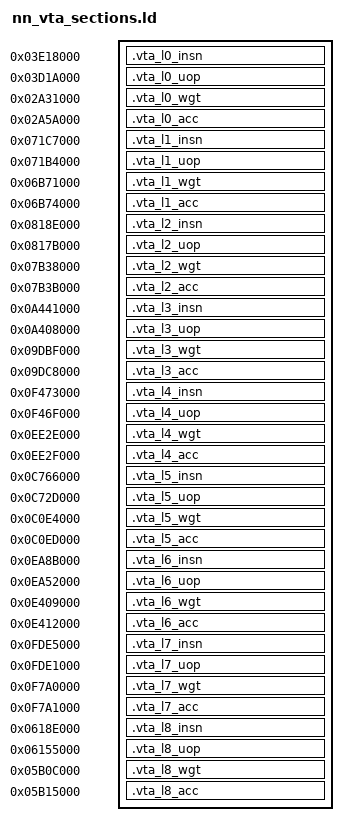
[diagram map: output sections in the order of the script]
/* Auto-generated by gen_nn_baremetal.py - DO NOT EDIT              */
/* VTA static model data linker fragment                             */
/*                                                                   */
/* Include this file inside the platform linker script generated.                    */
/* Example (in your lscript.ld):           */
/*   INCLUDE ../gen/nn_vta_sections.ld                                */

SECTIONS {
.vta_l0_insn 0x03E18000 : { KEEP(*(.vta_l0_insn)) }
.vta_l0_uop 0x03D1A000 : { KEEP(*(.vta_l0_uop)) }
.vta_l0_wgt 0x02A31000 : { KEEP(*(.vta_l0_wgt)) }
.vta_l0_acc 0x02A5A000 : { KEEP(*(.vta_l0_acc)) }
.vta_l1_insn 0x071C7000 : { KEEP(*(.vta_l1_insn)) }
.vta_l1_uop 0x071B4000 : { KEEP(*(.vta_l1_uop)) }
.vta_l1_wgt 0x06B71000 : { KEEP(*(.vta_l1_wgt)) }
.vta_l1_acc 0x06B74000 : { KEEP(*(.vta_l1_acc)) }
.vta_l2_insn 0x0818E000 : { KEEP(*(.vta_l2_insn)) }
.vta_l2_uop 0x0817B000 : { KEEP(*(.vta_l2_uop)) }
.vta_l2_wgt 0x07B38000 : { KEEP(*(.vta_l2_wgt)) }
.vta_l2_acc 0x07B3B000 : { KEEP(*(.vta_l2_acc)) }
.vta_l3_insn 0x0A441000 : { KEEP(*(.vta_l3_insn)) }
.vta_l3_uop 0x0A408000 : { KEEP(*(.vta_l3_uop)) }
.vta_l3_wgt 0x09DBF000 : { KEEP(*(.vta_l3_wgt)) }
.vta_l3_acc 0x09DC8000 : { KEEP(*(.vta_l3_acc)) }
.vta_l4_insn 0x0F473000 : { KEEP(*(.vta_l4_insn)) }
.vta_l4_uop 0x0F46F000 : { KEEP(*(.vta_l4_uop)) }
.vta_l4_wgt 0x0EE2E000 : { KEEP(*(.vta_l4_wgt)) }
.vta_l4_acc 0x0EE2F000 : { KEEP(*(.vta_l4_acc)) }
.vta_l5_insn 0x0C766000 : { KEEP(*(.vta_l5_insn)) }
.vta_l5_uop 0x0C72D000 : { KEEP(*(.vta_l5_uop)) }
.vta_l5_wgt 0x0C0E4000 : { KEEP(*(.vta_l5_wgt)) }
.vta_l5_acc 0x0C0ED000 : { KEEP(*(.vta_l5_acc)) }
.vta_l6_insn 0x0EA8B000 : { KEEP(*(.vta_l6_insn)) }
.vta_l6_uop 0x0EA52000 : { KEEP(*(.vta_l6_uop)) }
.vta_l6_wgt 0x0E409000 : { KEEP(*(.vta_l6_wgt)) }
.vta_l6_acc 0x0E412000 : { KEEP(*(.vta_l6_acc)) }
.vta_l7_insn 0x0FDE5000 : { KEEP(*(.vta_l7_insn)) }
.vta_l7_uop 0x0FDE1000 : { KEEP(*(.vta_l7_uop)) }
.vta_l7_wgt 0x0F7A0000 : { KEEP(*(.vta_l7_wgt)) }
.vta_l7_acc 0x0F7A1000 : { KEEP(*(.vta_l7_acc)) }
.vta_l8_insn 0x0618E000 : { KEEP(*(.vta_l8_insn)) }
.vta_l8_uop 0x06155000 : { KEEP(*(.vta_l8_uop)) }
.vta_l8_wgt 0x05B0C000 : { KEEP(*(.vta_l8_wgt)) }
.vta_l8_acc 0x05B15000 : { KEEP(*(.vta_l8_acc)) }
}
